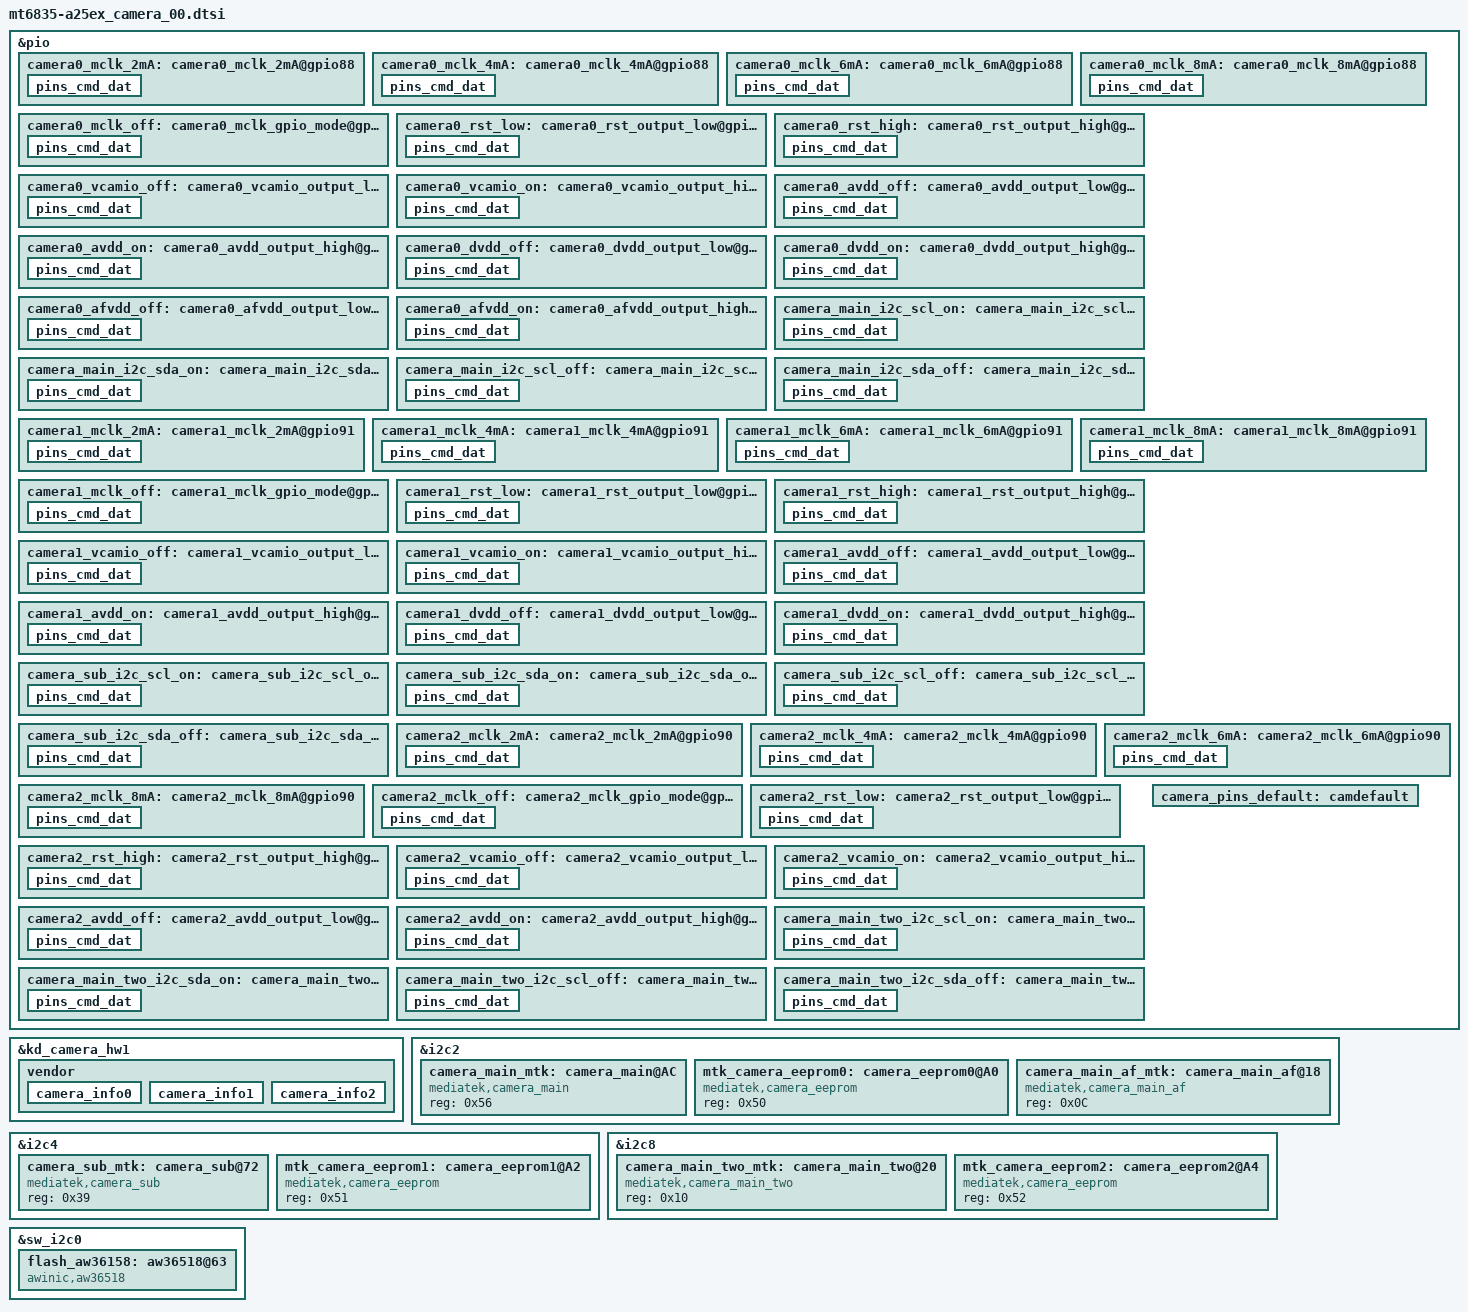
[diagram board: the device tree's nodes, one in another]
/*
 * Copyright (c) 2024 MediaTek Inc.
 *
 * This program is free software; you can redistribute it and/or modify
 * it under the terms of the GNU General Public License version 2 as
 * published by the Free Software Foundation.
 *
 * This program is distributed in the hope that it will be useful,
 * but WITHOUT ANY WARRANTY; without even the implied warranty of
 * MERCHANTABILITY or FITNESS FOR A PARTICULAR PURPOSE.  See the
 * GNU General Public License for more details.
 */

/********  A25e-5G Board  ***********
 *    SW          :   HW   : Sensor
 * camera0(Wide)  : RCAM1  : S5KJN1
 * camera1(Front) : FCAM   : SC501CS
 * camera2(Macro) : RCAM2  : GC02M1
 ***********************************/

/* CAMERA GPIO standardization */
&pio {
	/****************  Camera0  ***************/
	// MCLK
	camera0_mclk_2mA: camera0_mclk_2mA@gpio88 {
		pins_cmd_dat {
			pinmux = <PINMUX_GPIO88__FUNC_CMMCLK0>;
			drive-strength = <0>;
		};
	};
	camera0_mclk_4mA: camera0_mclk_4mA@gpio88 {
		pins_cmd_dat {
			pinmux = <PINMUX_GPIO88__FUNC_CMMCLK0>;
			drive-strength = <1>;
		};
	};
	camera0_mclk_6mA: camera0_mclk_6mA@gpio88 {
		pins_cmd_dat {
			pinmux = <PINMUX_GPIO88__FUNC_CMMCLK0>;
			drive-strength = <2>;
		};
	};
	camera0_mclk_8mA: camera0_mclk_8mA@gpio88 {
		pins_cmd_dat {
			pinmux = <PINMUX_GPIO88__FUNC_CMMCLK0>;
			drive-strength = <3>;
		};
	};
	camera0_mclk_off: camera0_mclk_gpio_mode@gpio88 {
		pins_cmd_dat {
			pinmux = <PINMUX_GPIO88__FUNC_GPIO88>;
			drive-strength = <1>;
		};
	};

	// Reset
	camera0_rst_low: camera0_rst_output_low@gpio25 {
		pins_cmd_dat {
			pinmux = <PINMUX_GPIO25__FUNC_GPIO25>;
			output-low;
		};
	};
	camera0_rst_high: camera0_rst_output_high@gpio25 {
		pins_cmd_dat {
			pinmux = <PINMUX_GPIO25__FUNC_GPIO25>;
			output-high;
		};
	};

	// IOVDD
	camera0_vcamio_off: camera0_vcamio_output_low@gpio108 {
		pins_cmd_dat {
			pinmux = <PINMUX_GPIO108__FUNC_GPIO108>;
			output-low;
		};
	};
	camera0_vcamio_on: camera0_vcamio_output_high@gpio108 {
		pins_cmd_dat {
			pinmux = <PINMUX_GPIO108__FUNC_GPIO108>;
			output-high;
		};
	};
	
	// AVDD
	camera0_avdd_off: camera0_avdd_output_low@gpio112 {
		pins_cmd_dat {
			pinmux = <PINMUX_GPIO112__FUNC_GPIO112>;
			output-low;
		};
	};
	camera0_avdd_on: camera0_avdd_output_high@gpio112 {
		pins_cmd_dat {
			pinmux = <PINMUX_GPIO112__FUNC_GPIO112>;
			output-high;
		};
	};

	// DVDD
	camera0_dvdd_off: camera0_dvdd_output_low@gpio113 {
		pins_cmd_dat {
			pinmux = <PINMUX_GPIO113__FUNC_GPIO113>;
			output-low;
		};
	};
	camera0_dvdd_on: camera0_dvdd_output_high@gpio113 {
		pins_cmd_dat {
			pinmux = <PINMUX_GPIO113__FUNC_GPIO113>;
			output-high;
		};
	};

	// AFVDD
	camera0_afvdd_off: camera0_afvdd_output_low@gpio111 {
		pins_cmd_dat {
			pinmux = <PINMUX_GPIO111__FUNC_GPIO111>;
			output-low;
		};
	};
	camera0_afvdd_on: camera0_afvdd_output_high@gpio111 {
		pins_cmd_dat {
			pinmux = <PINMUX_GPIO111__FUNC_GPIO111>;
			output-high;
		};
	};

	// I2C
	camera_main_i2c_scl_on: camera_main_i2c_scl_on@gpio131 {
		pins_cmd_dat {
			pinmux = <PINMUX_GPIO131__FUNC_SCL2>;
			bias-disable;
		};
	};
	camera_main_i2c_sda_on: camera_main_i2c_sda_on@gpio132 {
		pins_cmd_dat {
			pinmux = <PINMUX_GPIO132__FUNC_SDA2>;
			bias-disable;
		};
	};
	camera_main_i2c_scl_off: camera_main_i2c_scl_off@gpio131 {
		pins_cmd_dat {
			pinmux = <PINMUX_GPIO131__FUNC_GPIO131>;
			bias-disable;
		};
	};
	camera_main_i2c_sda_off: camera_main_i2c_sda_off@gpio132 {
		pins_cmd_dat {
			pinmux = <PINMUX_GPIO132__FUNC_GPIO132>;
			bias-disable;
		};
	};

	/****************  Camera1  ***************/
	// MCLK
	camera1_mclk_2mA: camera1_mclk_2mA@gpio91 {
		pins_cmd_dat {
			pinmux = <PINMUX_GPIO91__FUNC_CMMCLK3>;
			drive-strength = <0>;
		};
	};
	camera1_mclk_4mA: camera1_mclk_4mA@gpio91 {
		pins_cmd_dat {
			pinmux = <PINMUX_GPIO91__FUNC_CMMCLK3>;
			drive-strength = <1>;
		};
	};
	camera1_mclk_6mA: camera1_mclk_6mA@gpio91 {
		pins_cmd_dat {
			pinmux = <PINMUX_GPIO91__FUNC_CMMCLK3>;
			drive-strength = <2>;
		};
	};
	camera1_mclk_8mA: camera1_mclk_8mA@gpio91 {
		pins_cmd_dat {
			pinmux = <PINMUX_GPIO91__FUNC_CMMCLK3>;
			drive-strength = <3>;
		};
	};
	camera1_mclk_off: camera1_mclk_gpio_mode@gpio91 {
		pins_cmd_dat {
			pinmux = <PINMUX_GPIO91__FUNC_GPIO91>;
			drive-strength = <1>;
		};
	};

	// Reset
	camera1_rst_low: camera1_rst_output_low@gpio21 {
		pins_cmd_dat {
			pinmux = <PINMUX_GPIO21__FUNC_GPIO21>;
			output-low;
		};
	};
	camera1_rst_high: camera1_rst_output_high@gpio21 {
		pins_cmd_dat {
			pinmux = <PINMUX_GPIO21__FUNC_GPIO21>;
			output-high;
		};
	};

	// IOVDD
	camera1_vcamio_off: camera1_vcamio_output_low@gpio108 {
		pins_cmd_dat {
			pinmux = <PINMUX_GPIO108__FUNC_GPIO108>;
			output-low;
		};
	};
	camera1_vcamio_on: camera1_vcamio_output_high@gpio108 {
		pins_cmd_dat {
			pinmux = <PINMUX_GPIO108__FUNC_GPIO108>;
			output-high;
		};
	};

	// AVDD
	camera1_avdd_off: camera1_avdd_output_low@gpio109 {
		pins_cmd_dat {
			pinmux = <PINMUX_GPIO109__FUNC_GPIO109>;
			output-low;
		};
	};
	camera1_avdd_on: camera1_avdd_output_high@gpio109 {
		pins_cmd_dat {
			pinmux = <PINMUX_GPIO109__FUNC_GPIO109>;
			output-high;
		};
	};

	// DVDD
	camera1_dvdd_off: camera1_dvdd_output_low@gpio110 {
		pins_cmd_dat {
			pinmux = <PINMUX_GPIO110__FUNC_GPIO110>;
			output-low;
		};
	};
	camera1_dvdd_on: camera1_dvdd_output_high@gpio110 {
		pins_cmd_dat {
			pinmux = <PINMUX_GPIO110__FUNC_GPIO110>;
			output-high;
		};
	};
	
	// I2C
	camera_sub_i2c_scl_on: camera_sub_i2c_scl_on@gpio135 {
		pins_cmd_dat {
			pinmux = <PINMUX_GPIO135__FUNC_SCL4>;
			bias-pull-up;
		};
	};
	camera_sub_i2c_sda_on: camera_sub_i2c_sda_on@gpio136 {
		pins_cmd_dat {
			pinmux = <PINMUX_GPIO136__FUNC_SDA4>;
			bias-pull-up;
		};
	};
	camera_sub_i2c_scl_off: camera_sub_i2c_scl_off@gpio135 {
		pins_cmd_dat {
			pinmux = <PINMUX_GPIO135__FUNC_GPIO135>;
			bias-pull-down;
		};
	};
	camera_sub_i2c_sda_off: camera_sub_i2c_sda_off@gpio136 {
		pins_cmd_dat {
			pinmux = <PINMUX_GPIO136__FUNC_GPIO136>;
			bias-pull-down;
		};
	};

	/****************  Camera2  ***************/
	// MCLK
	camera2_mclk_2mA: camera2_mclk_2mA@gpio90 {
		pins_cmd_dat {
			pinmux = <PINMUX_GPIO90__FUNC_CMMCLK2>;
			drive-strength = <0>;
		};
	};
	camera2_mclk_4mA: camera2_mclk_4mA@gpio90 {
		pins_cmd_dat {
			pinmux = <PINMUX_GPIO90__FUNC_CMMCLK2>;
			drive-strength = <1>;
		};
	};
	camera2_mclk_6mA: camera2_mclk_6mA@gpio90 {
		pins_cmd_dat {
			pinmux = <PINMUX_GPIO90__FUNC_CMMCLK2>;
			drive-strength = <2>;
		};
	};
	camera2_mclk_8mA: camera2_mclk_8mA@gpio90 {
		pins_cmd_dat {
			pinmux = <PINMUX_GPIO90__FUNC_CMMCLK2>;
			drive-strength = <3>;
		};
	};
	camera2_mclk_off: camera2_mclk_gpio_mode@gpio90 {
		pins_cmd_dat {
			pinmux = <PINMUX_GPIO90__FUNC_GPIO90>;
			drive-strength = <1>;
		};
	};

	// Reset
	camera2_rst_low: camera2_rst_output_low@gpio26 {
		pins_cmd_dat {
			pinmux = <PINMUX_GPIO26__FUNC_GPIO26>;
			output-low;
		};
	};
	camera2_rst_high: camera2_rst_output_high@gpio26 {
		pins_cmd_dat {
			pinmux = <PINMUX_GPIO26__FUNC_GPIO26>;
			output-high;
		};
	};

	// IOVDD
	camera2_vcamio_off: camera2_vcamio_output_low@gpio108 {
		pins_cmd_dat {
			pinmux = <PINMUX_GPIO108__FUNC_GPIO108>;
			output-low;
		};
	};
	camera2_vcamio_on: camera2_vcamio_output_high@gpio108 {
		pins_cmd_dat {
			pinmux = <PINMUX_GPIO108__FUNC_GPIO108>;
			output-high;
		};
	};

	// AVDD
	camera2_avdd_off: camera2_avdd_output_low@gpio109 {
		pins_cmd_dat {
			pinmux = <PINMUX_GPIO109__FUNC_GPIO109>;
			output-low;
		};
	};
	camera2_avdd_on: camera2_avdd_output_high@gpio109 {
		pins_cmd_dat {
			pinmux = <PINMUX_GPIO109__FUNC_GPIO109>;
			output-high;
		};
	};

	// I2C
	camera_main_two_i2c_scl_on: camera_main_two_i2c_scl_on@gpio143 {
		pins_cmd_dat {
			pinmux = <PINMUX_GPIO143__FUNC_SCL8>;
			bias-pull-up;
		};
	};
	camera_main_two_i2c_sda_on: camera_main_two_i2c_sda_on@gpio144 {
		pins_cmd_dat {
			pinmux = <PINMUX_GPIO144__FUNC_SDA8>;
			bias-pull-up;
		};
	};
	camera_main_two_i2c_scl_off: camera_main_two_i2c_scl_off@gpio143 {
		pins_cmd_dat {
			pinmux = <PINMUX_GPIO143__FUNC_GPIO143>;
			bias-pull-down;
		};
	};
	camera_main_two_i2c_sda_off: camera_main_two_i2c_sda_off@gpio144 {
		pins_cmd_dat {
			pinmux = <PINMUX_GPIO144__FUNC_GPIO144>;
			bias-pull-down;
		};
	};

	camera_pins_default: camdefault {
	};
};

&kd_camera_hw1 {
	pinctrl-names = "default",
			"cam0_mclk_off",
			"cam0_mclk_2mA",  "cam0_mclk_4mA",
			"cam0_mclk_6mA",  "cam0_mclk_8mA",
			"cam0_rst0",       "cam0_rst1",
			"cam0_vcamio_off", "cam0_vcamio_on",
			"cam0_vcama_off",   "cam0_vcama_on",
			"cam0_vcamd_off",   "cam0_vcamd_on",
			"cam0_vcamaf_off",  "cam0_vcamaf_on",
			"cam0_vcamd1_off",   "cam0_vcamd1_on",
			"cam0_vcama1_off",   "cam0_vcama1_on",
			"cam0_rst1_off", "cam0_rst1_on",

			"cam1_mclk_off",
			"cam1_mclk_2mA", "cam1_mclk_4mA",
			"cam1_mclk_6mA", "cam1_mclk_8mA",
			"cam1_rst0", "cam1_rst1",
			"cam1_vcamio_off", "cam1_vcamio_on",
			"cam1_vcama_off",   "cam1_vcama_on",
			"cam1_vcamd_off",   "cam1_vcamd_on",

			"cam2_mclk_off",
			"cam2_mclk_2mA", "cam2_mclk_4mA",
			"cam2_mclk_6mA", "cam2_mclk_8mA",
			"cam2_rst0", "cam2_rst1",
			"cam2_vcamio_off", "cam2_vcamio_on",
			"cam2_vcama_off", "cam2_vcama_on",
			"cam2_vcamd1_off", "cam2_vcamd1_on",
			"cam2_rst1_off", "cam2_rst1_on";

	pinctrl-0 = <&camera_pins_default>;
	pinctrl-1 = <&camera0_mclk_off>;
	pinctrl-2 = <&camera0_mclk_2mA>;
	pinctrl-3 = <&camera0_mclk_4mA>;
	pinctrl-4 = <&camera0_mclk_6mA>;
	pinctrl-5 = <&camera0_mclk_8mA>;
	pinctrl-6 = <&camera0_rst_low>;
	pinctrl-7 = <&camera0_rst_high>;
	pinctrl-8 = <&camera0_vcamio_off>;
	pinctrl-9 = <&camera0_vcamio_on>;
	pinctrl-10 = <&camera0_avdd_off>;
	pinctrl-11 = <&camera0_avdd_on>;
	pinctrl-12 = <&camera0_dvdd_off>;
	pinctrl-13 = <&camera0_dvdd_on>;
	pinctrl-14 = <&camera0_afvdd_off>;
	pinctrl-15 = <&camera0_afvdd_on>;
	pinctrl-16 = <&camera1_dvdd_off>;
	pinctrl-17 = <&camera1_dvdd_on>;
	pinctrl-18 = <&camera1_avdd_off>;
	pinctrl-19 = <&camera1_avdd_on>;
	pinctrl-20 = <&camera1_rst_low>;
	pinctrl-21 = <&camera1_rst_high>;

	pinctrl-22 = <&camera1_mclk_off>;
	pinctrl-23 = <&camera1_mclk_2mA>;
	pinctrl-24 = <&camera1_mclk_4mA>;
	pinctrl-25 = <&camera1_mclk_6mA>;
	pinctrl-26 = <&camera1_mclk_8mA>;
	pinctrl-27 = <&camera1_rst_low>;
	pinctrl-28 = <&camera1_rst_high>;
	pinctrl-29 = <&camera1_vcamio_off>;
	pinctrl-30 = <&camera1_vcamio_on>;
	pinctrl-31 = <&camera1_avdd_off>;
	pinctrl-32 = <&camera1_avdd_on>;
	pinctrl-33 = <&camera1_dvdd_off>;
	pinctrl-34 = <&camera1_dvdd_on>;

	pinctrl-35 = <&camera2_mclk_off>;
	pinctrl-36 = <&camera2_mclk_2mA>;
	pinctrl-37 = <&camera2_mclk_4mA>;
	pinctrl-38 = <&camera2_mclk_6mA>;
	pinctrl-39 = <&camera2_mclk_8mA>;
	pinctrl-40 = <&camera2_rst_low>;
	pinctrl-41 = <&camera2_rst_high>;
	pinctrl-42 = <&camera2_vcamio_off>;
	pinctrl-43 = <&camera2_vcamio_on>;
	pinctrl-44 = <&camera2_avdd_off>;
	pinctrl-45 = <&camera2_avdd_on>;
	pinctrl-46 = <&camera1_dvdd_off>;
	pinctrl-47 = <&camera1_dvdd_on>;
	pinctrl-48 = <&camera1_rst_low>;
	pinctrl-49 = <&camera1_rst_high>;

	status = "okay";
	vendor {
		rear_sensor_id  = <120>;  /* SENSOR_NAME_S5KJN1 */
		front_sensor_id = <210>;  /* SENSOR_NAME_SC501CS */
		rear3_sensor_id = <211>;  /* SENSOR_NAME_GC02M1 */

		use_dualcam_set_cal;
		use_module_check;

		//skip_cal_loading;         /* for test without cal loading */
		//check_final_cam_module;   /* use after DVR */
		max_supported_camera = <3>;
		supported_cameraId = <56 1 60>; /* REAR, FRONT, REAR2 */

		max_camera_num = <3>;
		camera_info0 {             /* 0 : rear - S5KJN1 */
			isp = <0>;             /* 0 : INT , 1 : EXT , 2 : SOC */
			cal_memory = <2>;      /* 0 : N , 1 : FROM , 2 : EEPROM , 3 : OTP  */
			read_version = <0>;    /* 0 : SYSFS , 1 : CAMON */
			core_voltage = <0>;    /* 0 : N , 1 : Y  */
			upgrade = <0>;         /* 0 : N , 1 : SYSFS , 2 : CAMON */
			companion = <0>;       /* 0 : N , 1 : Y  */
			ois = <0>;             /* 0 : N , 1 : Y  */
			valid = <1>;           /* 0 : INVALID, 1 : VALID */
			dual_open = <0>;       /* 0 : SINGLE_OPEN , 1 : DUAL_OPEN */
			position = <0>;        /* 0 : Rear, 1:Front, 2:Rear2, 3:Front2, 4:Rear3, 6:Rear4 */
			//includes_sub = <4>;    /* include this for common eeprom. <_position_> - position of the sub camera */
			afcal_type=<20>;       /* output format - 1: Near, Middle..., Far , 20: Near, Far, Middle... */
			use_adaptive_mipi=<1>;  /* 0 : N, 1 : Y */
		};
		camera_info1 {             /* 1 : front1 - SC501CS */
			isp = <0>;             /* 0 : INT , 1 : EXT , 2 : SOC */
			cal_memory = <3>;      /* 0 : N , 1 : FROM , 2 : EEPROM , 3 : OTP  */
			read_version = <0>;    /* 0 : SYSFS , 1 : CAMON */
			core_voltage = <0>;    /* 0 : N , 1 : Y  */
			upgrade = <0>;         /* 0 : N , 1 : SYSFS , 2 : CAMON */
			companion = <0>;       /* 0 : N , 1 : Y  */
			ois = <0>;             /* 0 : N , 1 : Y  */
			valid = <1>;           /* 0 : INVALID, 1 : VALID */
			dual_open = <0>;       /* 0 : SINGLE_OPEN , 1 : DUAL_OPEN */
			position = <1>;        /* 0 : Rear, 1:Front, 2:Rear2, 3:Front2, 4:Rear3, 6:Rear4 */
			use_adaptive_mipi=<1>;  /* 0 : N, 1 : Y */
		};
		camera_info2{             /* 2: rear2- GC02M1*/
			isp = <0>;             /* 0 : INT , 1 : EXT , 2 : SOC */
			cal_memory = <2>;      /* 0 : N , 1 : FROM , 2 : EEPROM , 3 : OTP  */
			read_version = <0>;    /* 0 : SYSFS , 1 : CAMON */
			core_voltage = <0>;    /* 0 : N , 1 : Y  */
			upgrade = <0>;         /* 0 : N , 1 : SYSFS , 2 : CAMON */
			companion = <0>;       /* 0 : N , 1 : Y  */
			ois = <0>;             /* 0 : N , 1 : Y  */
			valid = <1>;           /* 0 : INVALID, 1 : VALID */
			dual_open = <0>;       /* 0 : SINGLE_OPEN , 1 : DUAL_OPEN */
			position = <2>;        /* 0 : Rear, 1:Front, 2:Rear2, 3:Front2, 4:Rear3, 6:Rear4 */
			use_adaptive_mipi=<0>;  /* 0 : N, 1 : Y */
		};
	};
};
/* CAMERA GPIO end */


/*************************
 *     Cmaera I2C
 *************************/
&i2c2 {
	status = "okay";
	#address-cells = <1>;
	#size-cells = <0>;
	clock-frequency = <1000000>;
	mediatek,use-open-drain;

	camera_main_mtk:camera_main@AC{
		compatible = "mediatek,camera_main";
		reg = <0x56>;
		status = "okay";
	};
	mtk_camera_eeprom0:camera_eeprom0@A0 {
		compatible = "mediatek,camera_eeprom";
		reg = <0x50>;
		status = "okay";
	};
	camera_main_af_mtk:camera_main_af@18 {
		compatible = "mediatek,camera_main_af";
		reg = <0x0C>;
		status = "okay";
	};
};

&i2c4 {
	status = "okay";
	#address-cells = <1>;
	#size-cells = <0>;
	clock-frequency = <1000000>;
	mediatek,use-open-drain;
	camera_sub_mtk:camera_sub@72 {
		compatible = "mediatek,camera_sub";
		reg = <0x39>;
		status = "okay";
	};
	mtk_camera_eeprom1:camera_eeprom1@A2 {
		compatible = "mediatek,camera_eeprom";
		reg = <0x51>;
		status = "okay";
	};
};

&i2c8 {
	status = "okay";
	#address-cells = <1>;
	#size-cells = <0>;
	clock-frequency = <400000>;
	mediatek,use-open-drain;

	camera_main_two_mtk:camera_main_two@20 {
		compatible = "mediatek,camera_main_two";
		reg = <0x10>;
		status = "okay";
	};
	mtk_camera_eeprom2:camera_eeprom2@A4 {
		compatible = "mediatek,camera_eeprom";
		reg = <0x52>;
		status = "okay";
	};
};

/*************************
 *     Flash LED
 *************************/
&sw_i2c0 {
	#address-cells = <1>;
	#size-cells = <0>;
	status = "okay";
	flash_aw36158:aw36518@63 {
		compatible = "awinic,aw36518";
		reg = <0x63>;
		is_flash = "Flash";
		status = "okay";
		flash-gpio = <&pio 165 0>;
		torch_level_1_cur = <50>;
		torch_level_2_cur = <75>;
		torch_level_3_cur = <125>;
		torch_level_4_cur = <175>;
		torch_level_5_cur = <225>;
		pre_flash_cur = <175>;
		main_flash_cur = <1250>;
		video_torch_cur = <50>;
	};
};

